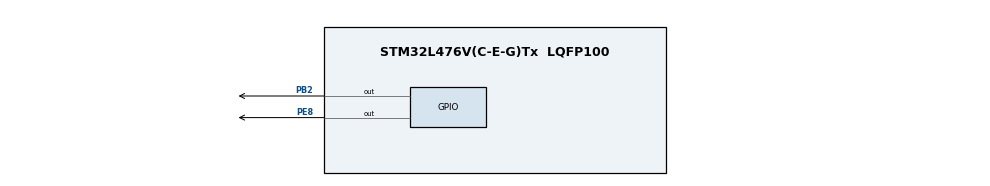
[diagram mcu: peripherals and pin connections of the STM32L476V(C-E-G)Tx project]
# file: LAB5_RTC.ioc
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Mcu.Family=STM32L4
Mcu.Name=STM32L476V(C-E-G)Tx
Mcu.Package=LQFP100
NVIC.PriorityGroup=NVIC_PRIORITYGROUP_4
NVIC.RTC_Alarm_IRQn=true\:0\:0\:false\:false\:true
PB2.Signal=GPIO_Output
PE8.Signal=GPIO_Output
ProjectManager.HeapSize=0x200
ProjectManager.StackSize=0x400
ProjectManager.TargetToolchain=EWARM
RCC.CortexFreq_Value=4000000
RCC.HSE_VALUE=8000000
RCC.HSI_VALUE=16000000
RCC.LSE_VALUE=32768
RCC.MSI_VALUE=4000000
RCC.PREFETCH_ENABLE=1
RCC.VCOOutputFreq_Value=32000000
RTC.Date=31
RTC.Hours=23
RTC.Minutes=59
RTC.Month=RTC_MONTH_DECEMBER
RTC.Seconds=45
RTC.Seconds_A-Alarm\ A=10
RTC.WeekDay=RTC_WEEKDAY_SUNDAY
RTC.Year=0
VP_RTC_VS_RTC_Alarm_A_Intern.Mode=Alarm A
board=STM32L476G-DISCO

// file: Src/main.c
#include "stm32l4xx_hal.h"

RTC_HandleTypeDef hrtc;
uint32_t value;
/* USER CODE BEGIN PV */
/* Private variables ---------------------------------------------------------*/
  RTC_TimeTypeDef sTime;
  RTC_DateTypeDef sDate;
  RTC_AlarmTypeDef sAlarm;
  uint32_t time_buff[7]  ;

/* USER CODE END PV */

void SystemClock_Config(void);
void Error_Handler(void);
static void MX_GPIO_Init(void);
static void MX_RTC_Init(void);

/* USER CODE BEGIN PFP */
/* Private function prototypes -----------------------------------------------*/

/* USER CODE END PFP */

int main(void)
{

  /* MCU Configuration----------------------------------------------------------*/

  /* Reset of all peripherals, Initializes the Flash interface and the Systick. */
  HAL_Init();

  /* Configure the system clock */
  SystemClock_Config();

  /* Initialize all configured peripherals */
  MX_GPIO_Init();
  MX_RTC_Init();

    value  = HAL_RCC_GetSysClockFreq();
    HAL_SuspendTick();
    HAL_PWR_EnterSLEEPMode(PWR_LOWPOWERREGULATOR_ON,PWR_SLEEPENTRY_WFI);
    HAL_ResumeTick();

  /* Infinite loop */
  while (1)
  {

  /* USER CODE BEGIN 3 */
HAL_RTC_GetTime(&hrtc,&sTime, RTC_FORMAT_BIN);
HAL_RTC_GetDate(&hrtc,&sDate, RTC_FORMAT_BIN);
HAL_GPIO_TogglePin(GPIOB,GPIO_PIN_2);
HAL_Delay(200);
time_buff[0] = sTime.Seconds ;
time_buff[1] = sTime.Minutes ;
time_buff[2] = sTime.Hours ;
time_buff[3] = sDate.WeekDay ;
time_buff[4] = sDate.Date ;
time_buff[5] = sDate.Month ;
time_buff[6] = sDate.Year;
value  = HAL_RCC_GetSysClockFreq();
  }
  /* USER CODE END 3 */

}

/** System Clock Configuration
*/
void SystemClock_Config(void)
{

  RCC_OscInitTypeDef RCC_OscInitStruct;
  RCC_ClkInitTypeDef RCC_ClkInitStruct;
  RCC_PeriphCLKInitTypeDef PeriphClkInit;

  RCC_OscInitStruct.OscillatorType = RCC_OSCILLATORTYPE_LSI|RCC_OSCILLATORTYPE_MSI;
  RCC_OscInitStruct.LSIState = RCC_LSI_ON;
  RCC_OscInitStruct.MSIState = RCC_MSI_ON;
  RCC_OscInitStruct.MSICalibrationValue = 0;
  RCC_OscInitStruct.MSIClockRange = RCC_MSIRANGE_4;
  RCC_OscInitStruct.PLL.PLLState = RCC_PLL_NONE;
  if (HAL_RCC_OscConfig(&RCC_OscInitStruct) != HAL_OK)
  {
    Error_Handler();
  }

  RCC_ClkInitStruct.ClockType = RCC_CLOCKTYPE_HCLK|RCC_CLOCKTYPE_SYSCLK
                              |RCC_CLOCKTYPE_PCLK1|RCC_CLOCKTYPE_PCLK2;
  RCC_ClkInitStruct.SYSCLKSource = RCC_SYSCLKSOURCE_MSI;
  RCC_ClkInitStruct.AHBCLKDivider = RCC_SYSCLK_DIV1;
  RCC_ClkInitStruct.APB1CLKDivider = RCC_HCLK_DIV1;
  RCC_ClkInitStruct.APB2CLKDivider = RCC_HCLK_DIV1;
  if (HAL_RCC_ClockConfig(&RCC_ClkInitStruct, FLASH_LATENCY_0) != HAL_OK)
  {
    Error_Handler();
  }

  PeriphClkInit.PeriphClockSelection = RCC_PERIPHCLK_RTC;
  PeriphClkInit.RTCClockSelection = RCC_RTCCLKSOURCE_LSI;
  if (HAL_RCCEx_PeriphCLKConfig(&PeriphClkInit) != HAL_OK)
  {
    Error_Handler();
  }

  __HAL_RCC_PWR_CLK_ENABLE();

  if (HAL_PWREx_ControlVoltageScaling(PWR_REGULATOR_VOLTAGE_SCALE1) != HAL_OK)
  {
    Error_Handler();
  }

  HAL_SYSTICK_Config(HAL_RCC_GetHCLKFreq()/1000);

  HAL_SYSTICK_CLKSourceConfig(SYSTICK_CLKSOURCE_HCLK);

  /* SysTick_IRQn interrupt configuration */
  HAL_NVIC_SetPriority(SysTick_IRQn, 0, 0);
}

/* RTC init function */
static void MX_RTC_Init(void)
{
    /**Initialize RTC and set the Time and Date
    */
  hrtc.Instance = RTC;
  hrtc.Init.HourFormat = RTC_HOURFORMAT_24;
  hrtc.Init.AsynchPrediv = 127;
  hrtc.Init.SynchPrediv = 255;
  hrtc.Init.OutPut = RTC_OUTPUT_DISABLE;
  hrtc.Init.OutPutRemap = RTC_OUTPUT_REMAP_NONE;
  hrtc.Init.OutPutPolarity = RTC_OUTPUT_POLARITY_HIGH;
  hrtc.Init.OutPutType = RTC_OUTPUT_TYPE_OPENDRAIN;
  if (HAL_RTC_Init(&hrtc) != HAL_OK)
  {
    Error_Handler();
  }

  sTime.Hours = 00;
  sTime.Minutes = 00;
  sTime.Seconds = 00;
  sTime.DayLightSaving = RTC_DAYLIGHTSAVING_NONE;
  sTime.StoreOperation = RTC_STOREOPERATION_RESET;
  if (HAL_RTC_SetTime(&hrtc, &sTime, RTC_FORMAT_BIN) != HAL_OK)
  {
    Error_Handler();
  }

  sDate.WeekDay = RTC_WEEKDAY_SUNDAY;
  sDate.Month = RTC_MONTH_DECEMBER;
  sDate.Date = 1;
  sDate.Year = 17;

  if (HAL_RTC_SetDate(&hrtc, &sDate, RTC_FORMAT_BIN) != HAL_OK)
  {
    Error_Handler();
  }

    /**Enable the Alarm A
    */
  sAlarm.AlarmTime.Hours = 0;
  sAlarm.AlarmTime.Minutes = 0;
  sAlarm.AlarmTime.Seconds = 10;
  sAlarm.AlarmTime.SubSeconds = 0;
  sAlarm.AlarmTime.DayLightSaving = RTC_DAYLIGHTSAVING_NONE;
  sAlarm.AlarmTime.StoreOperation = RTC_STOREOPERATION_RESET;
  sAlarm.AlarmMask = RTC_ALARMMASK_MINUTES | RTC_ALARMMASK_HOURS | RTC_ALARMMASK_DATEWEEKDAY  ;
  sAlarm.AlarmSubSecondMask = RTC_ALARMSUBSECONDMASK_ALL;
  sAlarm.AlarmDateWeekDaySel = RTC_ALARMDATEWEEKDAYSEL_DATE;
  sAlarm.AlarmDateWeekDay = 1;
  sAlarm.Alarm = RTC_ALARM_A;
  if (HAL_RTC_SetAlarm_IT(&hrtc, &sAlarm,RTC_FORMAT_BIN) != HAL_OK)
  {
    Error_Handler();
  }

}

/** Configure pins as
        * Analog
        * Input
        * Output
        * EVENT_OUT
        * EXTI
*/
static void MX_GPIO_Init(void)
{

  GPIO_InitTypeDef GPIO_InitStruct;

  /* GPIO Ports Clock Enable */
  __HAL_RCC_GPIOB_CLK_ENABLE();
  __HAL_RCC_GPIOE_CLK_ENABLE();

  /*Configure GPIO pin Output Level */
  HAL_GPIO_WritePin(GPIOB, GPIO_PIN_2, GPIO_PIN_RESET);

  /*Configure GPIO pin Output Level */
  HAL_GPIO_WritePin(GPIOE, GPIO_PIN_8, GPIO_PIN_RESET);

  /*Configure GPIO pin : PB2 */
  GPIO_InitStruct.Pin = GPIO_PIN_2;
  GPIO_InitStruct.Mode = GPIO_MODE_OUTPUT_PP;
  GPIO_InitStruct.Pull = GPIO_NOPULL;
  GPIO_InitStruct.Speed = GPIO_SPEED_FREQ_LOW;
  HAL_GPIO_Init(GPIOB, &GPIO_InitStruct);

  /*Configure GPIO pin : PE8 */
  GPIO_InitStruct.Pin = GPIO_PIN_8;
  GPIO_InitStruct.Mode = GPIO_MODE_OUTPUT_PP;
  GPIO_InitStruct.Pull = GPIO_NOPULL;
  GPIO_InitStruct.Speed = GPIO_SPEED_FREQ_LOW;
  HAL_GPIO_Init(GPIOE, &GPIO_InitStruct);

}

/* USER CODE BEGIN 4 */
void HAL_RTC_AlarmAEventCallback(RTC_HandleTypeDef *hrtc)
{

  HAL_GPIO_TogglePin(GPIOE,GPIO_PIN_8);
  UNUSED(hrtc);
  /* NOTE : This function should not be modified, when the callback is needed,
            the HAL_RTC_AlarmAEventCallback could be implemented in the user file
   */
}
/* USER CODE END 4 */

void Error_Handler(void)
{
  while(1)
  {
  }
}

/************************ (C) COPYRIGHT STMicroelectronics *****END OF FILE****/
